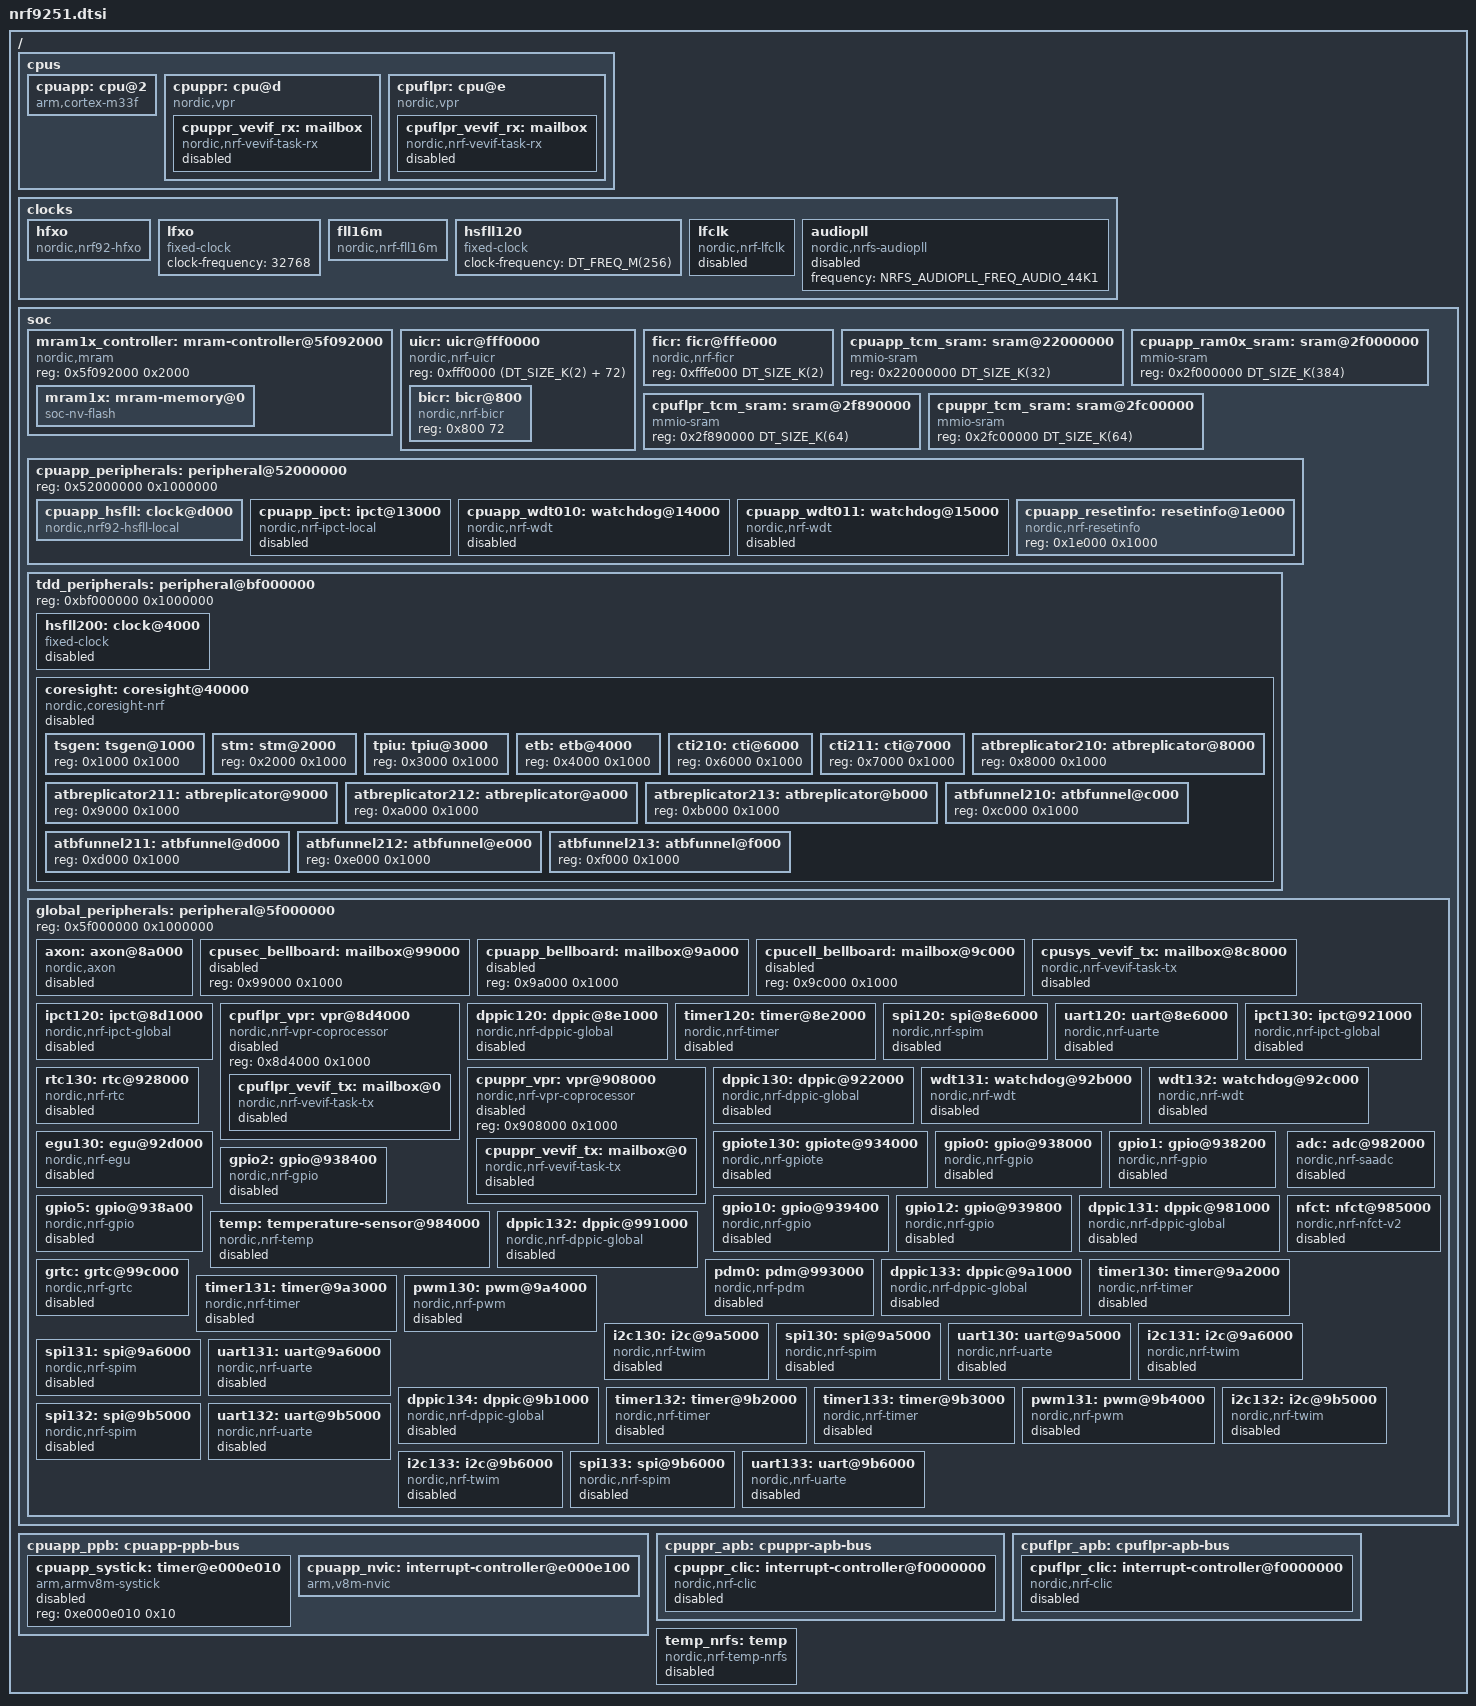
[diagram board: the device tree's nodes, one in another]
/*
 * Copyright (c) 2026 Nordic Semiconductor ASA
 *
 * SPDX-License-Identifier: LicenseRef-Nordic-5-Clause
 */

#include <mem.h>
#include <nordic/nrf_common.dtsi>
#include <zephyr/dt-bindings/adc/nrf-saadc.h>
#include <zephyr/dt-bindings/clock/nrfs-audiopll.h>
#include <dt-bindings/misc/nordic-nrf-ficr-nrf9220.h>
#include <dt-bindings/misc/nordic-domain-id-nrf9220.h>
#include <dt-bindings/misc/nordic-owner-id-nrf9220.h>

/delete-node/ &sw_pwm;

/ {
	#address-cells = <1>;
	#size-cells = <1>;

	cpus {
		#address-cells = <1>;
		#size-cells = <0>;

		cpuapp: cpu@2 {
			compatible = "arm,cortex-m33f";
			reg = <2>;
			device_type = "cpu";
			clocks = <&cpuapp_hsfll>;
			clock-frequency = <DT_FREQ_M(256)>;
		};

		cpuppr: cpu@d {
			compatible = "nordic,vpr", "riscv";
			reg = <13>;
			device_type = "cpu";
			clock-frequency = <DT_FREQ_M(16)>;
			riscv,isa-base = "rv32e";
			riscv,isa-extensions = "e", "m", "c", "zicsr";
			nordic,bus-width = <32>;

			cpuppr_vevif_rx: mailbox {
				compatible = "nordic,nrf-vevif-task-rx";
				status = "disabled";
				interrupt-parent = <&cpuppr_clic>;
				interrupts = <0 NRF_DEFAULT_IRQ_PRIORITY>,
					     <1 NRF_DEFAULT_IRQ_PRIORITY>,
					     <2 NRF_DEFAULT_IRQ_PRIORITY>,
					     <3 NRF_DEFAULT_IRQ_PRIORITY>,
					     <4 NRF_DEFAULT_IRQ_PRIORITY>,
					     <5 NRF_DEFAULT_IRQ_PRIORITY>,
					     <6 NRF_DEFAULT_IRQ_PRIORITY>,
					     <7 NRF_DEFAULT_IRQ_PRIORITY>,
					     <8 NRF_DEFAULT_IRQ_PRIORITY>,
					     <9 NRF_DEFAULT_IRQ_PRIORITY>,
					     <10 NRF_DEFAULT_IRQ_PRIORITY>,
					     <11 NRF_DEFAULT_IRQ_PRIORITY>,
					     <12 NRF_DEFAULT_IRQ_PRIORITY>,
					     <13 NRF_DEFAULT_IRQ_PRIORITY>,
					     <14 NRF_DEFAULT_IRQ_PRIORITY>,
					     <15 NRF_DEFAULT_IRQ_PRIORITY>;
				#mbox-cells = <1>;
				nordic,tasks = <16>;
				nordic,tasks-mask = <0x0000fff0>;
			};
		};

		cpuflpr: cpu@e {
			compatible = "nordic,vpr", "riscv";
			reg = <14>;
			device_type = "cpu";
			clock-frequency = <DT_FREQ_M(256)>;
			riscv,isa-base = "rv32e";
			riscv,isa-extensions = "e", "m", "c", "zicsr";
			nordic,bus-width = <64>;

			cpuflpr_vevif_rx: mailbox {
				compatible = "nordic,nrf-vevif-task-rx";
				status = "disabled";
				interrupt-parent = <&cpuflpr_clic>;
				interrupts = <0 NRF_DEFAULT_IRQ_PRIORITY>,
					     <1 NRF_DEFAULT_IRQ_PRIORITY>,
					     <2 NRF_DEFAULT_IRQ_PRIORITY>,
					     <3 NRF_DEFAULT_IRQ_PRIORITY>,
					     <4 NRF_DEFAULT_IRQ_PRIORITY>,
					     <5 NRF_DEFAULT_IRQ_PRIORITY>,
					     <6 NRF_DEFAULT_IRQ_PRIORITY>,
					     <7 NRF_DEFAULT_IRQ_PRIORITY>,
					     <8 NRF_DEFAULT_IRQ_PRIORITY>,
					     <9 NRF_DEFAULT_IRQ_PRIORITY>,
					     <10 NRF_DEFAULT_IRQ_PRIORITY>,
					     <11 NRF_DEFAULT_IRQ_PRIORITY>,
					     <12 NRF_DEFAULT_IRQ_PRIORITY>,
					     <13 NRF_DEFAULT_IRQ_PRIORITY>,
					     <14 NRF_DEFAULT_IRQ_PRIORITY>,
					     <15 NRF_DEFAULT_IRQ_PRIORITY>,
					     <16 NRF_DEFAULT_IRQ_PRIORITY>,
					     <17 NRF_DEFAULT_IRQ_PRIORITY>,
					     <18 NRF_DEFAULT_IRQ_PRIORITY>,
					     <19 NRF_DEFAULT_IRQ_PRIORITY>,
					     <20 NRF_DEFAULT_IRQ_PRIORITY>,
					     <21 NRF_DEFAULT_IRQ_PRIORITY>,
					     <22 NRF_DEFAULT_IRQ_PRIORITY>,
					     <23 NRF_DEFAULT_IRQ_PRIORITY>,
					     <24 NRF_DEFAULT_IRQ_PRIORITY>,
					     <25 NRF_DEFAULT_IRQ_PRIORITY>,
					     <26 NRF_DEFAULT_IRQ_PRIORITY>,
					     <27 NRF_DEFAULT_IRQ_PRIORITY>,
					     <28 NRF_DEFAULT_IRQ_PRIORITY>,
					     <29 NRF_DEFAULT_IRQ_PRIORITY>,
					     <30 NRF_DEFAULT_IRQ_PRIORITY>,
					     <31 NRF_DEFAULT_IRQ_PRIORITY>;
				#mbox-cells = <1>;
				nordic,tasks = <32>;
				nordic,tasks-mask = <0xffff0000>;
			};
		};
	};

	clocks {
		hfxo: hfxo {
			compatible = "nordic,nrf92-hfxo";
			#clock-cells = <0>;
			clock-frequency = <DT_FREQ_M(32)>;
			accuracy-ppm = <30>;
		};

		lfxo: lfxo {
			compatible = "fixed-clock";
			#clock-cells = <0>;
			clock-frequency = <32768>;
		};

		fll16m: fll16m {
			compatible = "nordic,nrf-fll16m";
			#clock-cells = <0>;
			clock-frequency = <DT_FREQ_M(16)>;
			open-loop-accuracy-ppm = <20000>;
			open-loop-startup-time-us = <200>; /* To be measured */
			clocks = <&hfxo>, <&lfxo>;
			clock-names = "hfxo", "lfxo";
		};

		hsfll120: hsfll120 {
			compatible = "fixed-clock";
			#clock-cells = <0>;
			clock-frequency = <DT_FREQ_M(256)>;
		};

		lfclk: lfclk {
			compatible = "nordic,nrf-lfclk";
			status = "disabled";
			#clock-cells = <0>;
			clock-frequency = <32768>;
			lfrc-accuracy-ppm = <500>;
			lflprc-accuracy-ppm = <1000>;
			lfrc-startup-time-us = <200>; /* To be measured */
			lflprc-startup-time-us = <200>; /* To be measured */
			clocks = <&hfxo>, <&lfxo>;
			clock-names = "hfxo", "lfxo";
		};

		audiopll: audiopll {
			compatible = "nordic,nrfs-audiopll";
			frequency = <NRFS_AUDIOPLL_FREQ_AUDIO_44K1>;
			status = "disabled";
		};
	};

	soc {
		#address-cells = <1>;
		#size-cells = <1>;
		ranges;

		mram1x_controller: mram-controller@5f092000 {
			compatible = "nordic,mram";
			reg = <0x5f092000 0x2000>;
			ranges = <0x0 0xe000000 DT_SIZE_K(6144)>;
			#address-cells = <1>;
			#size-cells = <1>;

			mram1x: mram-memory@0 {
				compatible = "soc-nv-flash";
				reg = <0 DT_SIZE_K(6144)>;
				ranges;
				erase-block-size = <4096>;
				write-block-size = <16>;
				#address-cells = <1>;
				#size-cells = <1>;
			};
		};

		uicr: uicr@fff0000 {
			compatible = "nordic,nrf-uicr";
			reg = <0xfff0000 (DT_SIZE_K(2) + 72)>;
			#address-cells = <1>;
			#size-cells = <1>;
			ranges = <0x0 0xfff0000 (DT_SIZE_K(2) + 72)>;

			bicr: bicr@800 {
				compatible = "nordic,nrf-bicr";
				reg = <0x800 72>;
			};
		};

		ficr: ficr@fffe000 {
			compatible = "nordic,nrf-ficr";
			reg = <0xfffe000 DT_SIZE_K(2)>;
			#nordic,ficr-cells = <1>;
		};

		cpuapp_tcm_sram: sram@22000000 {
			compatible = "mmio-sram";
			reg = <0x22000000 DT_SIZE_K(32)>;
			#address-cells = <1>;
			#size-cells = <1>;
			ranges = <0x0 0x22000000 0x8000>;
		};

		cpuapp_ram0x_sram: sram@2f000000 {
			compatible = "mmio-sram";
			reg = <0x2f000000 DT_SIZE_K(384)>;
			#address-cells = <1>;
			#size-cells = <1>;
			ranges = <0x0 0x2f000000 0x60000>;
		};

		cpuflpr_tcm_sram: sram@2f890000 {
			compatible = "mmio-sram";
			reg = <0x2f890000 DT_SIZE_K(64)>;
			#address-cells = <1>;
			#size-cells = <1>;
			ranges = <0x0 0x2f890000 0x10000>;
		};

		cpuppr_tcm_sram: sram@2fc00000 {
			compatible = "mmio-sram";
			reg = <0x2fc00000 DT_SIZE_K(64)>;
			#address-cells = <1>;
			#size-cells = <1>;
			ranges = <0x0 0x2fc00000 0x10000>;
		};

		cpuapp_peripherals: peripheral@52000000 {
			#address-cells = <1>;
			#size-cells = <1>;
			reg = <0x52000000 0x1000000>;
			ranges = <0x0 0x52000000 0x1000000>;

			cpuapp_hsfll: clock@d000 {
				compatible = "nordic,nrf92-hsfll-local";
				#clock-cells = <0>;
				reg = <0xd000 0x1000>;
				clocks = <&fll16m>;
				clock-frequency = <DT_FREQ_M(256)>;
				nordic,ficrs = <&ficr NRF_FICR_TRIM_APPLICATION_HSFLL_TRIM_VSUP>,
					       <&ficr
						NRF_FICR_TRIM_APPLICATION_HSFLL_TRIM_COARSE_0>,
					       <&ficr NRF_FICR_TRIM_APPLICATION_HSFLL_TRIM_FINE_0>;
				nordic,ficr-names = "vsup", "coarse", "fine";
			};

			cpuapp_ipct: ipct@13000 {
				compatible = "nordic,nrf-ipct-local";
				reg = <0x13000 0x1000>;
				status = "disabled";
				channels = <4>;
				interrupts = <64 NRF_DEFAULT_IRQ_PRIORITY>,
					     <65 NRF_DEFAULT_IRQ_PRIORITY>;
			};

			cpuapp_wdt010: watchdog@14000 {
				compatible = "nordic,nrf-wdt";
				reg = <0x14000 0x1000>;
				status = "disabled";
				interrupts = <20 NRF_DEFAULT_IRQ_PRIORITY>;
				clocks = <&lfclk>;
			};

			cpuapp_wdt011: watchdog@15000 {
				compatible = "nordic,nrf-wdt";
				reg = <0x15000 0x1000>;
				status = "disabled";
				interrupts = <21 NRF_DEFAULT_IRQ_PRIORITY>;
				clocks = <&lfclk>;
			};

			cpuapp_resetinfo: resetinfo@1e000 {
				compatible = "nordic,nrf-resetinfo";
				reg = <0x1e000 0x1000>;
			};
		};

		tdd_peripherals: peripheral@bf000000 {
			#address-cells = <1>;
			#size-cells = <1>;
			reg = <0xbf000000 0x1000000>;
			ranges = <0x0 0xbf000000 0x1000000>;

			hsfll200: clock@4000 {
				compatible = "fixed-clock";
				reg = <0x4000 0x1000>;
				#clock-cells = <0>;
				status = "disabled";
				clock-frequency = <DT_FREQ_M(400)>;
			};

			coresight: coresight@40000 {
				compatible = "nordic,coresight-nrf";
				reg = <0x40000 0x11000>;
				status = "disabled";
				clocks = <&hsfll200>;
				nordic,clockpin-enable = <NRF_FUN_TPIU_CLOCK>;
				#address-cells = <1>;
				#size-cells = <1>;
				ranges = <0x0 0x40000 0x11000>;

				tsgen: tsgen@1000 {
					reg = <0x1000 0x1000>;
				};

				stm: stm@2000 {
					reg = <0x2000 0x1000>;
				};

				tpiu: tpiu@3000 {
					reg = <0x3000 0x1000>;
				};

				etb: etb@4000 {
					reg = <0x4000 0x1000>;
				};

				cti210: cti@6000 {
					reg = <0x6000 0x1000>;
				};

				cti211: cti@7000 {
					reg = <0x7000 0x1000>;
				};

				atbreplicator210: atbreplicator@8000 {
					reg = <0x8000 0x1000>;
				};

				atbreplicator211: atbreplicator@9000 {
					reg = <0x9000 0x1000>;
				};

				atbreplicator212: atbreplicator@a000 {
					reg = <0xa000 0x1000>;
				};

				atbreplicator213: atbreplicator@b000 {
					reg = <0xb000 0x1000>;
				};

				atbfunnel210: atbfunnel@c000 {
					reg = <0xc000 0x1000>;
				};

				atbfunnel211: atbfunnel@d000 {
					reg = <0xd000 0x1000>;
				};

				atbfunnel212: atbfunnel@e000 {
					reg = <0xe000 0x1000>;
				};

				atbfunnel213: atbfunnel@f000 {
					reg = <0xf000 0x1000>;
				};
			};
		};

		global_peripherals: peripheral@5f000000 {
			#address-cells = <1>;
			#size-cells = <1>;
			ranges = <0x0 0x5f000000 0x1000000>;
			reg = <0x5f000000 0x1000000>;

			axon: axon@8a000 {
				compatible = "nordic,axon";
				reg = <0x8a000 0x1000>;
				interrupts = <138 NRF_DEFAULT_IRQ_PRIORITY>;
				status = "disabled";
			};

			cpusec_bellboard: mailbox@99000 {
				reg = <0x99000 0x1000>;
				status = "disabled";
				#mbox-cells = <1>;
			};

			cpuapp_bellboard: mailbox@9a000 {
				reg = <0x9a000 0x1000>;
				status = "disabled";
				#mbox-cells = <1>;
			};

			cpucell_bellboard: mailbox@9c000 {
				reg = <0x9c000 0x1000>;
				status = "disabled";
				#mbox-cells = <1>;
			};

			cpusys_vevif_tx: mailbox@8c8000 {
				compatible = "nordic,nrf-vevif-task-tx";
				reg = <0x8c8000 0x1000>;
				status = "disabled";
				#mbox-cells = <1>;
				nordic,tasks = <32>;
				nordic,tasks-mask = <0xfffff0ff>;
			};

			ipct120: ipct@8d1000 {
				compatible = "nordic,nrf-ipct-global";
				reg = <0x8d1000 0x1000>;
				status = "disabled";
				channels = <8>;
				global-domain-id = <12>;
			};

			cpuflpr_vpr: vpr@8d4000 {
				compatible = "nordic,nrf-vpr-coprocessor";
				reg = <0x8d4000 0x1000>;
				status = "disabled";
				#address-cells = <1>;
				#size-cells = <1>;
				ranges = <0x0 0x8d4000 0x1000>;

				cpuflpr_vevif_tx: mailbox@0 {
					compatible = "nordic,nrf-vevif-task-tx";
					reg = <0x0 0x1000>;
					status = "disabled";
					#mbox-cells = <1>;
					nordic,tasks = <32>;
					nordic,tasks-mask = <0xffff0000>;
				};
			};

			dppic120: dppic@8e1000 {
				compatible = "nordic,nrf-dppic-global";
				reg = <0x8e1000 0x1000>;
				channels = <8>;
				groups = <2>;
				status = "disabled";
				channels = <8>;
				groups = <2>;
			};

			timer120: timer@8e2000 {
				compatible = "nordic,nrf-timer";
				reg = <0x8e2000 0x1000>;
				status = "disabled";
				cc-num = <6>;
				interrupts = <226 NRF_DEFAULT_IRQ_PRIORITY>;
				max-bit-width = <32>;
				clocks = <&hsfll120>;
				prescaler = <0>;
			};

			spi120: spi@8e6000 {
				compatible = "nordic,nrf-spim";
				reg = <0x8e6000 0x1000>;
				status = "disabled";
				clocks = <&hsfll120>;
				easydma-maxcnt-bits = <15>;
				interrupts = <230 NRF_DEFAULT_IRQ_PRIORITY>;
				max-frequency = <DT_FREQ_M(32)>;
				#address-cells = <1>;
				#size-cells = <0>;
				rx-delay-supported;
				rx-delay = <1>;
				nordic,clockpin-enable = <NRF_FUN_SPIM_SCK>,
							 <NRF_FUN_SPIS_SCK>;
			};

			uart120: uart@8e6000 {
				compatible = "nordic,nrf-uarte";
				reg = <0x8e6000 0x1000>;
				status = "disabled";
				interrupts = <230 NRF_DEFAULT_IRQ_PRIORITY>;
				clocks = <&hsfll120>;
				endtx-stoptx-supported;
				frame-timeout-supported;
			};

			cpuppr_vpr: vpr@908000 {
				compatible = "nordic,nrf-vpr-coprocessor";
				reg = <0x908000 0x1000>;
				status = "disabled";
				#address-cells = <1>;
				#size-cells = <1>;
				ranges = <0x0 0x908000 0x1000>;

				cpuppr_vevif_tx: mailbox@0 {
					compatible = "nordic,nrf-vevif-task-tx";
					reg = <0x0 0x1000>;
					status = "disabled";
					#mbox-cells = <1>;
					nordic,tasks = <16>;
					nordic,tasks-mask = <0x0000fff0>;
				};
			};

			ipct130: ipct@921000 {
				compatible = "nordic,nrf-ipct-global";
				reg = <0x921000 0x1000>;
				status = "disabled";
				channels = <8>;
				global-domain-id = <13>;
			};

			dppic130: dppic@922000 {
				compatible = "nordic,nrf-dppic-global";
				reg = <0x922000 0x1000>;
				channels = <8>;
				groups = <2>;
				status = "disabled";
				channels = <8>;
				groups = <2>;
			};

			rtc130: rtc@928000 {
				compatible = "nordic,nrf-rtc";
				reg = <0x928000 0x1000>;
				status = "disabled";
				cc-num = <4>;
				clock-frequency = <32768>;
				interrupts = <296 NRF_DEFAULT_IRQ_PRIORITY>;
				clocks = <&lfclk>;
				prescaler = <1>;
			};

			wdt131: watchdog@92b000 {
				compatible = "nordic,nrf-wdt";
				reg = <0x92b000 0x1000>;
				status = "disabled";
				interrupts = <299 NRF_DEFAULT_IRQ_PRIORITY>;
				clocks = <&lfclk>;
			};

			wdt132: watchdog@92c000 {
				compatible = "nordic,nrf-wdt";
				reg = <0x92c000 0x1000>;
				status = "disabled";
				interrupts = <300 NRF_DEFAULT_IRQ_PRIORITY>;
				clocks = <&lfclk>;
			};

			egu130: egu@92d000 {
				compatible = "nordic,nrf-egu";
				reg = <0x92d000 0x1000>;
				status = "disabled";
				interrupts = <301 NRF_DEFAULT_IRQ_PRIORITY>;
			};

			gpiote130: gpiote@934000 {
				compatible = "nordic,nrf-gpiote";
				reg = <0x934000 0x1000>;
				status = "disabled";
				instance = <130>;
			};

			gpio0: gpio@938000 {
				compatible = "nordic,nrf-gpio";
				reg = <0x938000 0x200>;
				status = "disabled";
				#gpio-cells = <2>;
				gpio-controller;
				gpiote-instance = <&gpiote130>;
				ngpios = <5>;
				port = <0>;
			};

			gpio1: gpio@938200 {
				compatible = "nordic,nrf-gpio";
				reg = <0x938200 0x200>;
				status = "disabled";
				#gpio-cells = <2>;
				gpio-controller;
				gpiote-instance = <&gpiote130>;
				ngpios = <12>;
				port = <1>;
			};

			gpio2: gpio@938400 {
				compatible = "nordic,nrf-gpio";
				reg = <0x938400 0x200>;
				status = "disabled";
				#gpio-cells = <2>;
				gpio-controller;
				gpiote-instance = <&gpiote130>;
				ngpios = <10>;
				port = <2>;
			};

			gpio5: gpio@938a00 {
				compatible = "nordic,nrf-gpio";
				reg = <0x938a00 0x200>;
				status = "disabled";
				#gpio-cells = <2>;
				gpio-controller;
				ngpios = <6>;
				port = <5>;
			};

			gpio10: gpio@939400 {
				compatible = "nordic,nrf-gpio";
				reg = <0x939400 0x200>;
				status = "disabled";
				#gpio-cells = <2>;
				gpio-controller;
				ngpios = <8>;
				port = <10>;
			};

			gpio12: gpio@939800 {
				compatible = "nordic,nrf-gpio";
				reg = <0x939800 0x200>;
				status = "disabled";
				#gpio-cells = <2>;
				gpio-controller;
				gpiote-instance = <&gpiote130>;
				ngpios = <3>;
				port = <12>;
			};

			dppic131: dppic@981000 {
				compatible = "nordic,nrf-dppic-global";
				reg = <0x981000 0x1000>;
				channels = <8>;
				groups = <2>;
				status = "disabled";
				channels = <8>;
				groups = <2>;
			};

			adc: adc@982000 {
				compatible = "nordic,nrf-saadc";
				reg = <0x982000 0x1000>;
				interrupts = <386 NRF_DEFAULT_IRQ_PRIORITY>;
				status = "disabled";
				#io-channel-cells = <1>;
			};

			temp: temperature-sensor@984000 {
				compatible = "nordic,nrf-temp";
				reg = <0x984000 0x1000>;
				interrupts = <388 NRF_DEFAULT_IRQ_PRIORITY>;
				status = "disabled";
			};

			nfct: nfct@985000 {
				compatible = "nordic,nrf-nfct-v2";
				reg = <0x985000 0x1000>;
				status = "disabled";
				interrupts = <389 NRF_DEFAULT_IRQ_PRIORITY>;
			};

			dppic132: dppic@991000 {
				compatible = "nordic,nrf-dppic-global";
				reg = <0x991000 0x1000>;
				channels = <8>;
				groups = <2>;
				status = "disabled";
				channels = <8>;
				groups = <2>;
			};

			pdm0: pdm@993000 {
				compatible = "nordic,nrf-pdm";
				reg = <0x993000 0x1000>;
				status = "disabled";
				interrupts = <403 NRF_DEFAULT_IRQ_PRIORITY>;
				nordic,clockpin-enable = <NRF_FUN_PDM_CLK>;
			};

			grtc: grtc@99c000 {
				compatible = "nordic,nrf-grtc";
				reg = <0x99c000 0x1000>;
				status = "disabled";
				cc-num = <20>;
				clocks = <&lfclk>, <&fll16m>;
				clock-names = "lfclock", "hfclock";
			};

			dppic133: dppic@9a1000 {
				compatible = "nordic,nrf-dppic-global";
				reg = <0x9a1000 0x1000>;
				channels = <8>;
				groups = <2>;
				status = "disabled";
				channels = <8>;
				groups = <2>;
			};

			timer130: timer@9a2000 {
				compatible = "nordic,nrf-timer";
				reg = <0x9a2000 0x1000>;
				status = "disabled";
				cc-num = <6>;
				interrupts = <418 NRF_DEFAULT_IRQ_PRIORITY>;
				max-bit-width = <32>;
				prescaler = <0>;
				clocks = <&fll16m>;
			};

			timer131: timer@9a3000 {
				compatible = "nordic,nrf-timer";
				reg = <0x9a3000 0x1000>;
				status = "disabled";
				cc-num = <6>;
				interrupts = <419 NRF_DEFAULT_IRQ_PRIORITY>;
				max-bit-width = <32>;
				prescaler = <0>;
				clocks = <&fll16m>;
			};

			pwm130: pwm@9a4000 {
				compatible = "nordic,nrf-pwm";
				reg = <0x9a4000 0x1000>;
				status = "disabled";
				interrupts = <420 NRF_DEFAULT_IRQ_PRIORITY>;
				#pwm-cells = <3>;
			};

			i2c130: i2c@9a5000 {
				compatible = "nordic,nrf-twim";
				reg = <0x9a5000 0x1000>;
				status = "disabled";
				interrupts = <421 NRF_DEFAULT_IRQ_PRIORITY>;
				easydma-maxcnt-bits = <15>;
				clocks = <&fll16m>;
				#address-cells = <1>;
				#size-cells = <0>;
				nordic,clockpin-enable = <NRF_FUN_TWIM_SDA>,
							 <NRF_FUN_TWIM_SCL>;
				zephyr,pm-device-runtime-auto;
			};

			spi130: spi@9a5000 {
				compatible = "nordic,nrf-spim";
				reg = <0x9a5000 0x1000>;
				status = "disabled";
				easydma-maxcnt-bits = <15>;
				interrupts = <421 NRF_DEFAULT_IRQ_PRIORITY>;
				max-frequency = <DT_FREQ_M(8)>;
				clocks = <&fll16m>;
				#address-cells = <1>;
				#size-cells = <0>;
				rx-delay-supported;
				rx-delay = <1>;
				nordic,clockpin-enable = <NRF_FUN_SPIM_MOSI>,
							 <NRF_FUN_SPIM_SCK>,
							 <NRF_FUN_SPIS_MISO>,
							 <NRF_FUN_SPIS_SCK>;
			};

			uart130: uart@9a5000 {
				compatible = "nordic,nrf-uarte";
				reg = <0x9a5000 0x1000>;
				status = "disabled";
				clocks = <&fll16m>;
				interrupts = <421 NRF_DEFAULT_IRQ_PRIORITY>;
				nordic,clockpin-enable = <NRF_FUN_UART_TX>;
				endtx-stoptx-supported;
				frame-timeout-supported;
			};

			i2c131: i2c@9a6000 {
				compatible = "nordic,nrf-twim";
				reg = <0x9a6000 0x1000>;
				status = "disabled";
				clocks = <&fll16m>;
				interrupts = <422 NRF_DEFAULT_IRQ_PRIORITY>;
				easydma-maxcnt-bits = <15>;
				#address-cells = <1>;
				#size-cells = <0>;
				nordic,clockpin-enable = <NRF_FUN_TWIM_SDA>,
							 <NRF_FUN_TWIM_SCL>;
				zephyr,pm-device-runtime-auto;
			};

			spi131: spi@9a6000 {
				compatible = "nordic,nrf-spim";
				reg = <0x9a6000 0x1000>;
				status = "disabled";
				easydma-maxcnt-bits = <15>;
				interrupts = <422 NRF_DEFAULT_IRQ_PRIORITY>;
				max-frequency = <DT_FREQ_M(8)>;
				clocks = <&fll16m>;
				#address-cells = <1>;
				#size-cells = <0>;
				rx-delay-supported;
				rx-delay = <1>;
				nordic,clockpin-enable = <NRF_FUN_SPIM_MOSI>,
							 <NRF_FUN_SPIM_SCK>,
							 <NRF_FUN_SPIS_MISO>,
							 <NRF_FUN_SPIS_SCK>;
			};

			uart131: uart@9a6000 {
				compatible = "nordic,nrf-uarte";
				reg = <0x9a6000 0x1000>;
				status = "disabled";
				clocks = <&fll16m>;
				interrupts = <422 NRF_DEFAULT_IRQ_PRIORITY>;
				nordic,clockpin-enable = <NRF_FUN_UART_TX>;
				endtx-stoptx-supported;
				frame-timeout-supported;
			};

			dppic134: dppic@9b1000 {
				compatible = "nordic,nrf-dppic-global";
				reg = <0x9b1000 0x1000>;
				channels = <8>;
				groups = <2>;
				status = "disabled";
				channels = <8>;
				groups = <2>;
			};

			timer132: timer@9b2000 {
				compatible = "nordic,nrf-timer";
				reg = <0x9b2000 0x1000>;
				status = "disabled";
				cc-num = <6>;
				interrupts = <434 NRF_DEFAULT_IRQ_PRIORITY>;
				max-bit-width = <32>;
				prescaler = <0>;
				clocks = <&fll16m>;
			};

			timer133: timer@9b3000 {
				compatible = "nordic,nrf-timer";
				reg = <0x9b3000 0x1000>;
				status = "disabled";
				cc-num = <6>;
				interrupts = <435 NRF_DEFAULT_IRQ_PRIORITY>;
				max-bit-width = <32>;
				prescaler = <0>;
				clocks = <&fll16m>;
			};

			pwm131: pwm@9b4000 {
				compatible = "nordic,nrf-pwm";
				reg = <0x9b4000 0x1000>;
				status = "disabled";
				interrupts = <436 NRF_DEFAULT_IRQ_PRIORITY>;
				#pwm-cells = <3>;
			};

			i2c132: i2c@9b5000 {
				compatible = "nordic,nrf-twim";
				reg = <0x9b5000 0x1000>;
				status = "disabled";
				interrupts = <437 NRF_DEFAULT_IRQ_PRIORITY>;
				easydma-maxcnt-bits = <15>;
				clocks = <&fll16m>;
				#address-cells = <1>;
				#size-cells = <0>;
				nordic,clockpin-enable = <NRF_FUN_TWIM_SDA>,
							 <NRF_FUN_TWIM_SCL>;
				zephyr,pm-device-runtime-auto;
			};

			spi132: spi@9b5000 {
				compatible = "nordic,nrf-spim";
				reg = <0x9b5000 0x1000>;
				status = "disabled";
				easydma-maxcnt-bits = <15>;
				interrupts = <437 NRF_DEFAULT_IRQ_PRIORITY>;
				max-frequency = <DT_FREQ_M(8)>;
				clocks = <&fll16m>;
				#address-cells = <1>;
				#size-cells = <0>;
				rx-delay-supported;
				rx-delay = <1>;
				nordic,clockpin-enable = <NRF_FUN_SPIM_MOSI>,
							 <NRF_FUN_SPIM_SCK>,
							 <NRF_FUN_SPIS_MISO>,
							 <NRF_FUN_SPIS_SCK>;
			};

			uart132: uart@9b5000 {
				compatible = "nordic,nrf-uarte";
				reg = <0x9b5000 0x1000>;
				status = "disabled";
				clocks = <&fll16m>;
				interrupts = <437 NRF_DEFAULT_IRQ_PRIORITY>;
				nordic,clockpin-enable = <NRF_FUN_UART_TX>;
				endtx-stoptx-supported;
				frame-timeout-supported;
			};

			i2c133: i2c@9b6000 {
				compatible = "nordic,nrf-twim";
				reg = <0x9b6000 0x1000>;
				status = "disabled";
				clocks = <&fll16m>;
				interrupts = <438 NRF_DEFAULT_IRQ_PRIORITY>;
				easydma-maxcnt-bits = <15>;
				#address-cells = <1>;
				#size-cells = <0>;
				nordic,clockpin-enable = <NRF_FUN_TWIM_SDA>,
							 <NRF_FUN_TWIM_SCL>;
				zephyr,pm-device-runtime-auto;
			};

			spi133: spi@9b6000 {
				compatible = "nordic,nrf-spim";
				reg = <0x9b6000 0x1000>;
				status = "disabled";
				easydma-maxcnt-bits = <15>;
				interrupts = <438 NRF_DEFAULT_IRQ_PRIORITY>;
				max-frequency = <DT_FREQ_M(8)>;
				clocks = <&fll16m>;
				#address-cells = <1>;
				#size-cells = <0>;
				rx-delay-supported;
				rx-delay = <1>;
				nordic,clockpin-enable = <NRF_FUN_SPIM_MOSI>,
							 <NRF_FUN_SPIM_SCK>,
							 <NRF_FUN_SPIS_MISO>,
							 <NRF_FUN_SPIS_SCK>;
			};

			uart133: uart@9b6000 {
				compatible = "nordic,nrf-uarte";
				reg = <0x9b6000 0x1000>;
				status = "disabled";
				clocks = <&fll16m>;
				interrupts = <438 NRF_DEFAULT_IRQ_PRIORITY>;
				nordic,clockpin-enable = <NRF_FUN_UART_TX>;
				endtx-stoptx-supported;
				frame-timeout-supported;
			};
		};
	};

	cpuapp_ppb: cpuapp-ppb-bus {
		#address-cells = <1>;
		#size-cells = <1>;

		cpuapp_systick: timer@e000e010 {
			compatible = "arm,armv8m-systick";
			reg = <0xe000e010 0x10>;
			status = "disabled";
		};

		cpuapp_nvic: interrupt-controller@e000e100 {
			compatible = "arm,v8m-nvic";
			reg = <0xe000e100 0xc00>;
			arm,num-irq-priority-bits = <3>;
			#interrupt-cells = <2>;
			interrupt-controller;
			#address-cells = <1>;
		};
	};

	cpuppr_apb: cpuppr-apb-bus {
		#address-cells = <1>;
		#size-cells = <1>;

		cpuppr_clic: interrupt-controller@f0000000 {
			compatible = "nordic,nrf-clic";
			reg = <0xf0000000 0x3000>;
			status = "disabled";
			#interrupt-cells = <2>;
			interrupt-controller;
			#address-cells = <1>;
		};
	};

	cpuflpr_apb: cpuflpr-apb-bus {
		#address-cells = <1>;
		#size-cells = <1>;

		cpuflpr_clic: interrupt-controller@f0000000 {
			compatible = "nordic,nrf-clic";
			reg = <0xf0000000 0x3000>;
			status = "disabled";
			#interrupt-cells = <2>;
			interrupt-controller;
			#address-cells = <1>;
		};
	};

	temp_nrfs: temp {
		compatible = "nordic,nrf-temp-nrfs";
		status = "disabled";
	};
};
